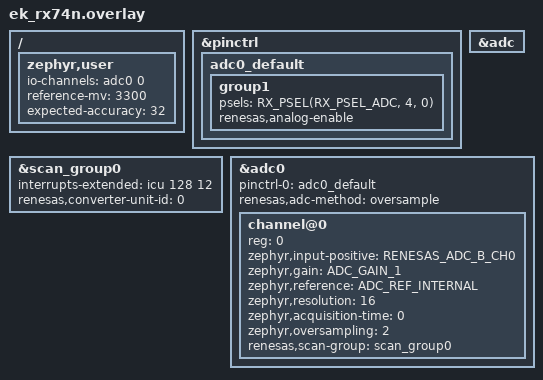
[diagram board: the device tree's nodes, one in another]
/*
 * Copyright (c) 2026 Renesas Electronics Corporation
 *
 * SPDX-License-Identifier: Apache-2.0
 */

/ {
	zephyr,user {
		io-channels = <&adc0 0>;
		reference-mv = <3300>;
		expected-accuracy = <32>;
	};
};

&pinctrl {
	adc0_default: adc0_default {
		group1 {
			/* input */
			psels = <RX_PSEL(RX_PSEL_ADC, 4, 0)>;
			renesas,analog-enable;
		};
	};
};

&adc {
	status = "okay";
};

&scan_group0 {
	interrupts-extended = <&icu 128 12>;
	interrupt-names = "scanend";
	renesas,converter-unit-id = <0>;
	status = "okay";
};

&adc0 {
	pinctrl-0 = <&adc0_default>;
	pinctrl-names = "default";
	renesas,adc-method = "oversample";
	status = "okay";
	#address-cells = <1>;
	#size-cells = <0>;

	channel@0 {
		reg = <0>;
		zephyr,input-positive = <RENESAS_ADC_B_CH0>;
		zephyr,gain = "ADC_GAIN_1";
		zephyr,reference = "ADC_REF_INTERNAL";
		zephyr,resolution = <16>;
		zephyr,acquisition-time = <0>;
		zephyr,oversampling = <2>;
		renesas,scan-group = <&scan_group0>;
	};
};
